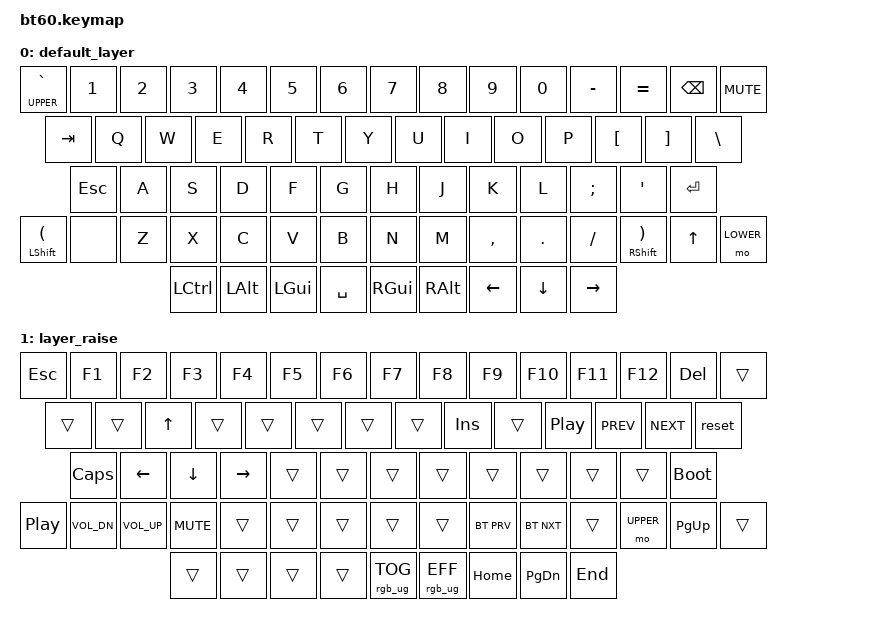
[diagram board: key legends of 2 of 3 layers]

/*
 * Copyright (c) 2020 The ZMK Contributors
 *
 * SPDX-License-Identifier: MIT
 */


/* THIS FILE WAS GENERATED!
 *
 * This file was generated automatically. You may or may not want to
 * edit it directly.
 */

#include <behaviors.dtsi>
#include <dt-bindings/zmk/keys.h>
#include <dt-bindings/zmk/bt.h>
#include <dt-bindings/zmk/rgb.h>
#include <dt-bindings/zmk/backlight.h>

#define DEFAULT 0
#define LOWER   1
#define UPPER   2

/ {
    keymap {
        compatible = "zmk,keymap";


        default_layer {
					bindings = < 
						&lt UPPER GRAVE  &kp N1  &kp N2  &kp N3  &kp N4  &kp N5  &kp N6  &kp N7  &kp N8  &kp N9  &kp N0  &kp MINUS  &kp EQUAL  &kp BSPC  &kp K_MUTE
						&kp TAB  &kp Q  &kp W  &kp E  &kp R  &kp T  &kp Y  &kp U  &kp I  &kp O  &kp P  &kp LBKT  &kp RBKT  &kp BSLH
						&kp ESC  &kp A  &kp S  &kp D  &kp F  &kp G  &kp H  &kp J  &kp K  &kp L  &kp SEMI  &kp SQT  &kp RET
						&mt LSHIFT LEFT_PARENTHESIS  &none  &kp Z  &kp X  &kp C  &kp V  &kp B  &kp N  &kp M  &kp COMMA  &kp DOT  &kp FSLH  &mt RIGHT_SHIFT RIGHT_PARENTHESIS  &kp UP  &mo LOWER
						&kp LCTRL  &kp LALT  &kp LGUI  &kp SPACE  &kp RGUI  &kp RALT  &kp LEFT  &kp DOWN  &kp RIGHT
					>;
					sensor-bindings = <&inc_dec_kp C_VOL_UP C_VOL_DN>;
        };

        layer_raise {
					bindings = <
						&kp ESC  &kp F1  &kp F2  &kp F3  &kp F4  &kp F5  &kp F6  &kp F7  &kp F8  &kp F9  &kp F10  &kp F11  &kp F12  &kp DEL  &trans
						&trans  &trans  &kp UP  &trans  &trans  &trans  &trans  &trans  &kp INS  &trans  &kp C_PLAY_PAUSE  &kp C_PREV  &kp C_NEXT  &reset
						&kp CLCK  &kp LEFT  &kp DOWN  &kp RIGHT  &trans  &trans  &trans  &trans  &trans  &trans  &trans  &trans  &bootloader
						&kp C_PLAY_PAUSE  &kp C_VOL_DN  &kp C_VOL_UP  &kp C_MUTE  &trans  &trans  &trans  &trans  &trans  &bt BT_PRV  &bt BT_NXT  &trans  &mo UPPER  &kp PG_UP  &trans
						&trans  &trans &trans  &trans  &rgb_ug RGB_TOG  &rgb_ug RGB_EFF  &kp HOME  &kp PG_DN  &kp END
					>;
					sensor-bindings = <&inc_dec_kp PG_UP PG_DN>;
        };

				layer_bt {
					bindings = <
						&trans  &bt BT_SEL 1  &bt BT_SEL 2  &bt BT_SEL 3  &bt BT_SEL 4  &bt BT_SEL 5  &trans  &trans  &trans  &trans  &trans  &bt BT_PRV  &bt BT_NXT  &bt BT_CLR  &trans
						&trans  &trans  &trans  &trans  &trans  &trans  &trans  &trans  &trans  &trans  &trans  &trans  &trans  &trans
						&trans  &trans  &trans  &trans  &trans  &trans  &trans  &trans  &trans  &trans  &trans  &trans  &trans
						&trans  &trans  &trans  &trans  &trans  &trans  &trans  &trans  &trans  &trans  &trans  &trans  &trans  &trans
						&rgb_ug RGB_TOG  &trans  &trans  &trans  &trans  &trans  &trans  &trans  &trans  
					>;
        };
    };
};
